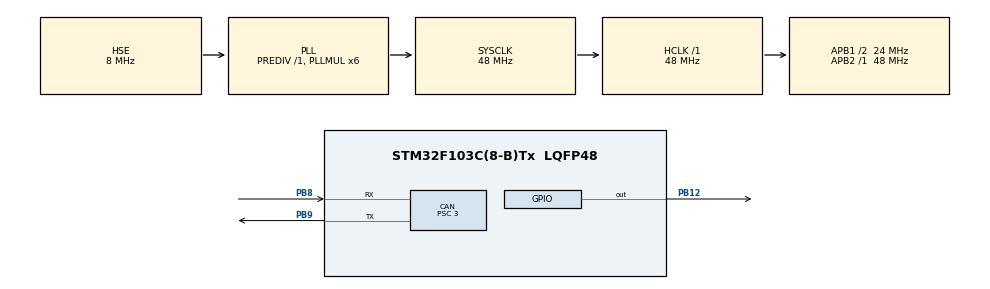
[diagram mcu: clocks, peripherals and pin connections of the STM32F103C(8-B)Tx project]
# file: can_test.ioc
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CAN.ABOM=ENABLE
CAN.BS1=CAN_BS1_13TQ
CAN.BS2=CAN_BS2_2TQ
CAN.CalculateBaudRate=500000
CAN.CalculateTimeBit=2000
CAN.CalculateTimeQuantum=125.0
CAN.Mode=CAN_MODE_SILENT_LOOPBACK
CAN.Prescaler=3
CAN.TXFP=ENABLE
Mcu.Family=STM32F1
Mcu.Name=STM32F103C(8-B)Tx
Mcu.Package=LQFP48
NVIC.CAN1_RX1_IRQn=true\:0\:0\:false\:false\:true\:true\:true\:true
NVIC.CAN1_SCE_IRQn=true\:0\:0\:false\:false\:true\:true\:true\:true
NVIC.PriorityGroup=NVIC_PRIORITYGROUP_4
PA13.Mode=Serial_Wire
PA13.Signal=SYS_JTMS-SWDIO
PA14.Mode=Serial_Wire
PA14.Signal=SYS_JTCK-SWCLK
PB12.PinState=GPIO_PIN_SET
PB12.Signal=GPIO_Output
PB8.Mode=CAN_Activate
PB8.Signal=CAN_RX
PB9.Mode=CAN_Activate
PB9.Signal=CAN_TX
PD0-OSC_IN.Mode=HSE-External-Oscillator
PD0-OSC_IN.Signal=RCC_OSC_IN
PD1-OSC_OUT.Mode=HSE-External-Oscillator
PD1-OSC_OUT.Signal=RCC_OSC_OUT
ProjectManager.HeapSize=0x200
ProjectManager.StackSize=0x400
ProjectManager.TargetToolchain=STM32CubeIDE
RCC.AHBFreq_Value=48000000
RCC.APB1CLKDivider=RCC_HCLK_DIV2
RCC.APB1Freq_Value=24000000
RCC.APB1TimFreq_Value=48000000
RCC.APB2Freq_Value=48000000
RCC.APB2TimFreq_Value=48000000
RCC.EnbaleCSS=true
RCC.HCLKFreq_Value=48000000
RCC.PLLMUL=RCC_PLL_MUL6
RCC.PLLSourceVirtual=RCC_PLLSOURCE_HSE
RCC.SYSCLKFreq_VALUE=48000000
RCC.SYSCLKSource=RCC_SYSCLKSOURCE_PLLCLK
RCC.USBFreq_Value=48000000
board=custom

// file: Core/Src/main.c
/* USER CODE BEGIN Header */
/**
 ******************************************************************************
 * @file           : main.c
 * @brief          : Main program body
 ******************************************************************************
 * @attention
 *
 * Copyright (c) 2024 STMicroelectronics.
 * All rights reserved.
 *
 * This software is licensed under terms that can be found in the LICENSE file
 * in the root directory of this software component.
 * If no LICENSE file comes with this software, it is provided AS-IS.
 *
 ******************************************************************************
 */
/* USER CODE END Header */
#include "main.h"

CAN_HandleTypeDef hcan;

/* USER CODE BEGIN PV */
CAN_TxHeaderTypeDef TxHeader;
CAN_RxHeaderTypeDef RxHeader;
uint8_t TxData[8] = { 0, };
uint8_t RxData[8] = { 0, };
uint32_t TxMailbox = 0;
/* USER CODE END PV */

void SystemClock_Config(void);
static void MX_GPIO_Init(void);
static void MX_CAN_Init(void);

int main(void)
{

  /* MCU Configuration--------------------------------------------------------*/

  /* Reset of all peripherals, Initializes the Flash interface and the Systick. */
  HAL_Init();

  /* Configure the system clock */
  SystemClock_Config();

  /* Initialize all configured peripherals */
  MX_GPIO_Init();
  MX_CAN_Init();
  /* USER CODE BEGIN 2 */
  // TxHeader.StdId = 0x0107;
  TxHeader.ExtId = 0;
  TxHeader.RTR = CAN_RTR_DATA; //CAN_RTR_REMOTE
  TxHeader.IDE = CAN_ID_STD;   // CAN_ID_EXT
  TxHeader.DLC = 8;
  TxHeader.TransmitGlobalTime = 0;

  // Заполняем массив для отправки данных
  for (uint8_t i = 0; i < 8; i++) {
    TxData[i] = i + 10;
  }

  /* USER CODE END 2 */

  /* Infinite loop */
  /* USER CODE BEGIN WHILE */
  // Запускаем CAN и активируем события которые будут вызывать прерывания
  HAL_CAN_Start(&hcan);
  HAL_CAN_ActivateNotification(&hcan, CAN_IT_RX_FIFO1_MSG_PENDING | CAN_IT_ERROR | CAN_IT_BUSOFF | CAN_IT_LAST_ERROR_CODE);

  while (1) {
    TxHeader.StdId = 0x0100;
    TxData[0] = 90;

    while (HAL_CAN_GetTxMailboxesFreeLevel(&hcan) == 0);

    if (HAL_CAN_AddTxMessage(&hcan, &TxHeader, TxData, &TxMailbox) != HAL_OK) {
      // Ошибка при отправке
      __NOP();
    }

    HAL_Delay(500);

    TxHeader.StdId = 0x0107;
    TxData[0] = 100;

    while (HAL_CAN_GetTxMailboxesFreeLevel(&hcan) == 0);

    if (HAL_CAN_AddTxMessage(&hcan, &TxHeader, TxData, &TxMailbox) != HAL_OK) {
      // Ошибка при отправке
      __NOP();
    }

    HAL_Delay(500);

    /* USER CODE END WHILE */

  }
}

void SystemClock_Config(void)
{
  RCC_OscInitTypeDef RCC_OscInitStruct = {0};
  RCC_ClkInitTypeDef RCC_ClkInitStruct = {0};

  /** Initializes the RCC Oscillators according to the specified parameters
  * in the RCC_OscInitTypeDef structure.
  */
  RCC_OscInitStruct.OscillatorType = RCC_OSCILLATORTYPE_HSE;
  RCC_OscInitStruct.HSEState = RCC_HSE_ON;
  RCC_OscInitStruct.HSEPredivValue = RCC_HSE_PREDIV_DIV1;
  RCC_OscInitStruct.HSIState = RCC_HSI_ON;
  RCC_OscInitStruct.PLL.PLLState = RCC_PLL_ON;
  RCC_OscInitStruct.PLL.PLLSource = RCC_PLLSOURCE_HSE;
  RCC_OscInitStruct.PLL.PLLMUL = RCC_PLL_MUL6;
  if (HAL_RCC_OscConfig(&RCC_OscInitStruct) != HAL_OK)
  {
    Error_Handler();
  }

  /** Initializes the CPU, AHB and APB buses clocks
  */
  RCC_ClkInitStruct.ClockType = RCC_CLOCKTYPE_HCLK|RCC_CLOCKTYPE_SYSCLK
                              |RCC_CLOCKTYPE_PCLK1|RCC_CLOCKTYPE_PCLK2;
  RCC_ClkInitStruct.SYSCLKSource = RCC_SYSCLKSOURCE_PLLCLK;
  RCC_ClkInitStruct.AHBCLKDivider = RCC_SYSCLK_DIV1;
  RCC_ClkInitStruct.APB1CLKDivider = RCC_HCLK_DIV2;
  RCC_ClkInitStruct.APB2CLKDivider = RCC_HCLK_DIV1;

  if (HAL_RCC_ClockConfig(&RCC_ClkInitStruct, FLASH_LATENCY_1) != HAL_OK)
  {
    Error_Handler();
  }

  /** Enables the Clock Security System
  */
  HAL_RCC_EnableCSS();
}

static void MX_CAN_Init(void)
{

  /* USER CODE BEGIN CAN_Init 0 */
  CAN_FilterTypeDef sFilterConfig;
  /* USER CODE END CAN_Init 0 */

  hcan.Instance = CAN1;
  hcan.Init.Prescaler = 3;
  hcan.Init.Mode = CAN_MODE_SILENT_LOOPBACK;
  hcan.Init.SyncJumpWidth = CAN_SJW_1TQ;
  hcan.Init.TimeSeg1 = CAN_BS1_13TQ;
  hcan.Init.TimeSeg2 = CAN_BS2_2TQ;
  hcan.Init.TimeTriggeredMode = DISABLE;
  hcan.Init.AutoBusOff = ENABLE;
  hcan.Init.AutoWakeUp = DISABLE;
  hcan.Init.AutoRetransmission = DISABLE;
  hcan.Init.ReceiveFifoLocked = DISABLE;
  hcan.Init.TransmitFifoPriority = ENABLE;
  if (HAL_CAN_Init(&hcan) != HAL_OK)
  {
    Error_Handler();
  }
  /* USER CODE BEGIN CAN_Init 2 */
  sFilterConfig.FilterBank = 0;
  sFilterConfig.FilterMode = CAN_FILTERMODE_IDMASK;
  sFilterConfig.FilterScale = CAN_FILTERSCALE_32BIT;
  sFilterConfig.FilterIdHigh = 0x0100 << 5; // старшая часть первого "регистра фильтра"
  sFilterConfig.FilterIdLow = 0x0000;     // младшая часть первого "регистра фильтра"
  sFilterConfig.FilterMaskIdHigh = 0x07F8 << 5; // старшая часть второго "регистра фильтра"
  sFilterConfig.FilterMaskIdLow = 0x0000;     // младшая часть второго "регистра фильтра"
  sFilterConfig.FilterFIFOAssignment = CAN_RX_FIFO1;
  sFilterConfig.FilterActivation = ENABLE;

  if (HAL_CAN_ConfigFilter(&hcan, &sFilterConfig) != HAL_OK) {
    Error_Handler();
  }
  /* USER CODE END CAN_Init 2 */

}

static void MX_GPIO_Init(void)
{
  GPIO_InitTypeDef GPIO_InitStruct = {0};

  /* GPIO Ports Clock Enable */
  __HAL_RCC_GPIOD_CLK_ENABLE();
  __HAL_RCC_GPIOB_CLK_ENABLE();
  __HAL_RCC_GPIOA_CLK_ENABLE();

  /*Configure GPIO pin Output Level */
  HAL_GPIO_WritePin(GPIOB, GPIO_PIN_12, GPIO_PIN_SET);

  /*Configure GPIO pin : PB12 */
  GPIO_InitStruct.Pin = GPIO_PIN_12;
  GPIO_InitStruct.Mode = GPIO_MODE_OUTPUT_PP;
  GPIO_InitStruct.Pull = GPIO_NOPULL;
  GPIO_InitStruct.Speed = GPIO_SPEED_FREQ_LOW;
  HAL_GPIO_Init(GPIOB, &GPIO_InitStruct);

}

/* USER CODE BEGIN 4 */
void HAL_CAN_RxFifo1MsgPendingCallback(CAN_HandleTypeDef *hcan) {
  if (hcan->Instance == CAN1) {
    if (HAL_CAN_GetRxMessage(hcan, CAN_RX_FIFO1, &RxHeader, RxData) == HAL_OK) {
      // Обрабатываем данные с буфера CAN_RX_FIFO1
      if (RxHeader.StdId == 0x0100) {
        __NOP();
      } else if (RxHeader.StdId == 0x0107) {
        __NOP();
      }
    }
  }
}

void HAL_CAN_ErrorCallback(CAN_HandleTypeDef *hcan) {
  if (hcan->Instance == CAN1) {
    // При любой ошибке зажигаем светодиод на PB12
    HAL_GPIO_WritePin(GPIOB, GPIO_PIN_12, GPIO_PIN_RESET);
  }
}

/* USER CODE END 4 */

void Error_Handler(void)
{
  __disable_irq();
  while (1) {
  }
}
